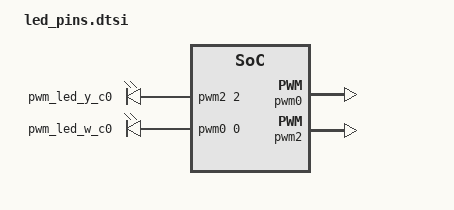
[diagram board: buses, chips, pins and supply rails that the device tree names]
/* Copyright 2023 The ChromiumOS Authors
 * Use of this source code is governed by a BSD-style license that can be
 * found in the LICENSE file.
 */

/ {
	pwmleds {
		compatible = "pwm-leds";
		pwm_led_y_c0: pwm_led_y_c0 {
			pwms = <&pwm2 2 PWM_HZ(324) PWM_POLARITY_INVERTED>;
		};
		pwm_led_w_c0: pwm_led_w_c0 {
			pwms = <&pwm0 0 PWM_HZ(324) PWM_POLARITY_INVERTED>;
		};
		/* reserve to use */
		pwms = <&pwm1 1 PWM_HZ(324) PWM_POLARITY_INVERTED>;
	};

	pwm-led-pins {
		compatible = "cros-ec,pwm-led-pins";

		battery_led: battery-led {
			led-id = "EC_LED_ID_BATTERY_LED";
			led-pwms = <&pwm_led_y_c0 &pwm_led_w_c0>;
			color-off {
				led-color = "LED_OFF";
				led-values = <0 0>;
			};

			color-amber {
				led-color = "LED_AMBER";
				led-values = <100 0>;
			};

			color-white {
				led-color = "LED_WHITE";
				led-values = <0 100>;
			};
		};
	};
};

/* LED2 */
&pwm0 {
	status = "okay";
	clock-bus = "NPCX_CLOCK_BUS_LFCLK";
	pinctrl-0 = <&pwm0_gpc3>;
	pinctrl-names = "default";
};

/* LED1 */
&pwm2 {
	status = "okay";
	clock-bus = "NPCX_CLOCK_BUS_LFCLK";
	pinctrl-0 = <&pwm2_gpc4>;
	pinctrl-names = "default";
};
